# IPU_UNICACHE_CFG register map
Vendor: Texas Instruments
Peripheral module from a debugger description file (folder TDA3x).
Registers are 32-bit, access per field, reset 0x0 unless marked. A register's access mark holds for its fields unless they carry their own. Offsets are as the file gives them; lines under a group give offsets from that group; [hi:lo] are bit positions; {n}, {i} and the like mark numbered series; 'fields as' and 'values as' point back to an identical list; <NAME> marks a mode.

## IPU_UNICACHE_CFG
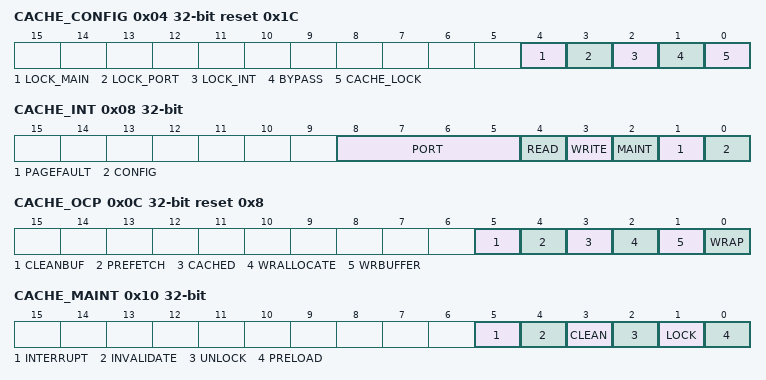
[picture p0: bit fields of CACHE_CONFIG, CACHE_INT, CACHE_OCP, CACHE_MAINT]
0x04 CACHE_CONFIG reset 0x1C — Configuration Register
  [4] LOCK_MAIN rw — Lock access to maintenance registers
    0=Locked; 1=Not_locked
  [3] LOCK_PORT rw — Lock access to interface registers
    0=Locked; 1=Not_locked
  [2] LOCK_INT rw — Lock access to interrupt registers
    0=Locked; 1=Not_locked
  [1] BYPASS rw — Bypass cache
    0=Everything_is_non-cacheable; 1=Everything_is_cacheable
  [0] CACHE_LOCK rw — Unicache lock. Once this bit is set only debugger or hardware reset can clear.
    0=No_effect; 1=Only_debug_accesses_allowed
0x08 CACHE_INT access not given — Interrupt Register
  [8:5] PORT — Slave interface number that has recorded an error (access RW W1toClr)
  [4] READ — Interface read response error (access RW W1toClr)
  [3] WRITE — Interface write response error (access RW W1toClr)
  [2] MAINT — Maintenance is completed (access RW W1toClr)
  [1] PAGEFAULT — Unicache MMU page fault (access RW W1toClr)
  [0] CONFIG — Configuration error (access RW W1toClr)
0x0C CACHE_OCP reset 0x8 — Interface Configuration Register
  [5] CLEANBUF rw — Clean write and prefetch buffers in cache
    0=Do_not_clean; 1=Clean
  [4] PREFETCH rw — Always prefetch data
    0=Follow_MMU_policies; 1=Always_prefetch
  [3] CACHED rw — Follow cacheable sideband signals
    0=Reads always not allocated, writes write through if cached; 1=Slave_sideband_signals_determine_policy
  [2] WRALLOCATE rw — Follow write allocate sideband signals
    0=No writes are allocated independent to sideband; 1=Follow_sideband
  [1] WRBUFFER rw — Write throughs and write back no allocate are buffered
    0=Write throughs and write back no allocated are not buffered; 1=Write throughs and write back no allocated are buffered
  [0] WRAP rw — OCP wrap mode (critical word first)
    0=Disabled; 1=Enabled
0x10 CACHE_MAINT — Maintenance Configuration Register
  [5] INTERRUPT rw — Generate interrupt when maintenance operation is complete
    0=Do_not_generate_interrupt; 1=Generate_interrupt
  [4] INVALIDATE rw — Invalidate lines in region defined by maintenance start/end addresses
    0=Do_nothing; 1=Invalidate
  [3] CLEAN rw — Evict dirty lines in region defined by maintenance start/end addresses
    0=Do_nothing; 1=Clean
  [2] UNLOCK rw — Unlock region defined by maintenance start/end addresses
    0=Do_nothing; 1=Unlock
  [1] LOCK rw — Lock region defined by maintenance start/end addresses
    0=Do_nothing; 1=Lock
  [0] PRELOAD rw — Preload region defined by maintenance start/end addresses
    0=Do_nothing; 1=Preload
0x14 CACHE_MTSTART rw — Maintenance Start Configuration Register
  [31:0] START_ADDR — Start address of maintenance operations, reset to 0x0000 0000 when finished
0x18 CACHE_MTEND rw — Maintenance End Configuration Register
  [31:0] END_ADDR — End address of maintenance operations, reset to 0x0000 0000 when finished
0x1C CACHE_CTADDR rw — Cache Test Address Register
  [31:0] ADDRESS — Address of cache visibility when readCACHE_CTDATA register, autoincrements
0x20 CACHE_CTDATA rw — Cache Test Data Register
  [31:0] DATA — Cache data at address ofCACHE_CTADDR register, CACHE_CTADDR autoincrements each time CACHE_CTDATA is read
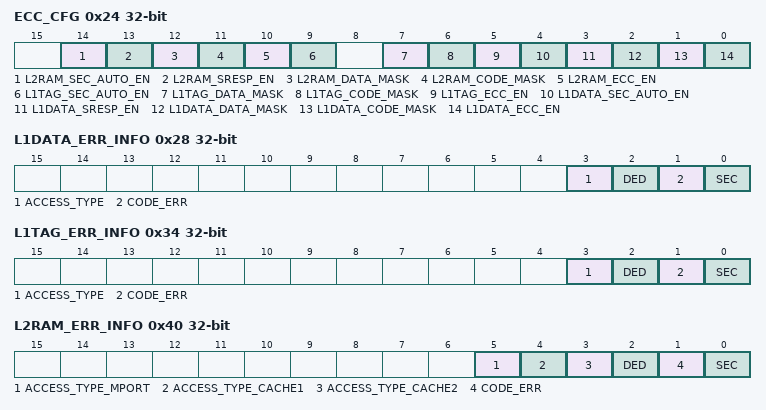
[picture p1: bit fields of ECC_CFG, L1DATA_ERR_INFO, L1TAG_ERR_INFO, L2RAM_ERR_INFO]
0x24 ECC_CFG — ECC configuration register
  [14] L2RAM_SEC_AUTO_EN rw — Enables auto-correction of data in case of SEC error in L2 RAM
  [13] L2RAM_SRESP_EN rw — Enables error response to master in case of DED error in L2 RAM
  [12] L2RAM_DATA_MASK rw — L2 RAM ECC Code Mask register. Enabling this will mask any write to data block while ECC will be updated on any writes to the memory. This is for test purpose.
  [11] L2RAM_CODE_MASK rw — L2 RAM ECC Code Mask register. Enabling this will mask any write to ECC code block of memory. This is for test purpose.
  [10] L2RAM_ECC_EN rw — L2 RAM ECC enable
  [9] L1TAG_SEC_AUTO_EN rw — Enables auto-correction of data in case of SEC error in L1 Tag
  [7] L1TAG_DATA_MASK rw — L1 Tag ECC Code Mask register. Enabling this will mask any write to data block while ECC will be updated on any writes to the memory. This is for test purpose.
  [6] L1TAG_CODE_MASK rw — L1 Tag ECC Code Mask register. Enabling this will mask any write to ECC code block of memory. This is for test purpose.
  [5] L1TAG_ECC_EN rw — L1 Tag ECC enable
  [4] L1DATA_SEC_AUTO_EN rw — Enables auto-correction of data in case of SEC error in L1 Data
  [3] L1DATA_SRESP_EN rw — Enables error response to master in case of DED error in L1 Data
  [2] L1DATA_DATA_MASK rw — L1 Data ECC Code Mask register. Enabling this will mask any write to data block while ECC will be updated on any writes to the memory. This is for test purpose.
  [1] L1DATA_CODE_MASK rw — L1 Data ECC Code Mask register. Enabling this will mask any write to ECC code block of memory. This is for test purpose.
  [0] L1DATA_ECC_EN rw — L1 Data ECC enable
0x28 L1DATA_ERR_INFO access not given — L1 Data ECC information register
  [3] ACCESS_TYPE — Indicates what access type resulted in ECC error in L1 Data 0 - indicates access other than eviction 1 - eviction (access RW W1toClr)
  [2] DED — Indicates DED error in L1 Data (access RW W1toClr)
  [1] CODE_ERR — Indicates SEC error in ECC code area of memory in L1 Data (access RW W1toClr)
  [0] SEC — Indicates SEC error in L1 Data (access RW W1toClr)
0x30 L1DATA_ERR_ADDR_LOC ro — Indicates address location of error occurence in L1 Data
  [31:0] ADDR_LOCATION — Indicates virtual address where ECC error has occured in L1 Data
0x34 L1TAG_ERR_INFO access not given — L1 Tag ECC information register
  [3] ACCESS_TYPE — Indicates what access type resulted in ECC error in L1 Tag 0 - indicates access other than eviction 1 - eviction (access RW W1toClr)
  [2] DED — Indicates DED error in L1 Tag (access RW W1toClr)
  [1] CODE_ERR — Indicates SEC error in ECC code area of memory in L1 Tag (access RW W1toClr)
  [0] SEC — Indicates SEC error in L1 Tag (access RW W1toClr)
0x3C L1TAG_ERR_ADDR_LOC ro — Indicates address location of error occurence in L1 Data
  [31:0] ADDR_LOCATION — Indicates virtual address for the access which resulted in an ECC error in L1 Tag memory.
0x40 L2RAM_ERR_INFO access not given — L2 RAM ECC information register
  [5] ACCESS_TYPE_MPORT — This bit is set whenever an access is made to L2RAM via the slave configuration interface. (access RW W1toClr)
  [4] ACCESS_TYPE_CACHE1 — This bit is set whenever an access is made to L2RAM via the Unicache interface. This will be set even if Cache is disabled. (access RW W1toClr)
  [3] ACCESS_TYPE_CACHE2 — This bit is reserved since L2 cache is not implemented in IPU subsystem. (access RW W1toClr)
  [2] DED — Indicates DED error in L2 RAM (access RW W1toClr)
  [1] CODE_ERR — Indicates SEC error in ECC code area of memory in L2 RAM (access RW W1toClr)
  [0] SEC — Indicates SEC error in L2 RAM (access RW W1toClr)
0x48 L2RAM_ERR_ADDR_LOC ro — Indicates address location of error occurence in L2 RAM
  [31:0] ADDR_LOCATION — Indicates physical address where ECC error has occured in L2RAM. The address reported is aligned to a 8 byte boundary.
